AUTOSAR XML (schema 00051)
package /ComponentTypes
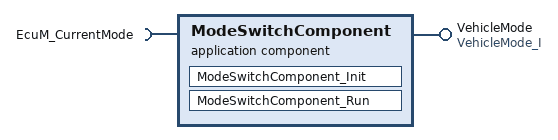
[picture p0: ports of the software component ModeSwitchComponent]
  application sw component type ModeSwitchComponent
    require port EcuM_CurrentMode: mode-switch-receiver-com-spec{enhanced-mode-api=false, mode-group=currentMode, supports-asynchronous-mode-switch=false}, required-interface=EcuM_CurrentMode
    provide port VehicleMode: mode-switch-sender-com-spec{enhanced-mode-api=false, mode-group=mode, mode-switched-ack=timeout=1}, provided-interface=VehicleMode_I
    behavior ModeSwitchComponent_InternalBehavior
      runnable ModeSwitchComponent_Init
      runnable ModeSwitchComponent_Run: mode-access-point=EcuM_CurrentMode.currentMode
        mode switch point SWITCH_VehicleMode_mode: mode-group=VehicleMode.mode
  swc implementation ModeSwitchComponent_Implementation: behavior=ModeSwitchComponent_InternalBehavior
